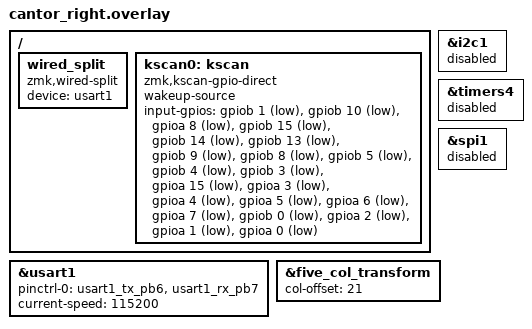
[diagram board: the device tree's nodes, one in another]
/*
 * Cantor right half – peripheral side (connects to left half via TRRS).
 *
 * Same GPIO pin order as the left half (same PCB, just flipped).
 * The col-offset=<21> shifts columns to 21-41, and the matrix transform
 * reverses the column order to handle the physical mirroring.
 *
 * Split communication: USART1 full-duplex on PB6 (TX) / PB7 (RX).
 */

#include "cantor.dtsi"

/*
 * Disable peripherals whose default pins conflict with Cantor GPIOs:
 *   - I2C1 uses PB8/PB9 → conflicts with kscan row-1 keys
 *   - TIM4/PWM4 uses PB6/PB7 → conflicts with USART1 wired split
 *   - SPI1 uses PA5/PA6/PA7 → conflicts with kscan row-2 keys
 */
&i2c1 { status = "disabled"; };
&timers4 { status = "disabled"; };
&spi1 { status = "disabled"; };

/* Remap USART1 to PB6/PB7 (Cantor wiring) and enable for wired split */
&usart1 {
    pinctrl-0 = <&usart1_tx_pb6 &usart1_rx_pb7>;
    pinctrl-names = "default";
    status = "okay";
    current-speed = <115200>;
};

/* Shift right-half column indices by 21 so they don't overlap with left */
&five_col_transform {
    col-offset = <21>;
};

/ {
    wired_split {
        compatible = "zmk,wired-split";
        device = <&usart1>;
    };

    kscan0: kscan {
        compatible = "zmk,kscan-gpio-direct";
        wakeup-source;
        input-gpios =
            <&gpiob 1  (GPIO_ACTIVE_LOW | GPIO_PULL_UP)>   /* row 0 col 0 (outer) */
            , <&gpiob 10 (GPIO_ACTIVE_LOW | GPIO_PULL_UP)> /* row 0 col 1 */
            , <&gpioa 8  (GPIO_ACTIVE_LOW | GPIO_PULL_UP)> /* row 0 col 2 */
            , <&gpiob 15 (GPIO_ACTIVE_LOW | GPIO_PULL_UP)> /* row 0 col 3 */
            , <&gpiob 14 (GPIO_ACTIVE_LOW | GPIO_PULL_UP)> /* row 0 col 4 */
            , <&gpiob 13 (GPIO_ACTIVE_LOW | GPIO_PULL_UP)> /* row 0 col 5 (inner) */
            , <&gpiob 9  (GPIO_ACTIVE_LOW | GPIO_PULL_UP)> /* row 1 col 0 */
            , <&gpiob 8  (GPIO_ACTIVE_LOW | GPIO_PULL_UP)> /* row 1 col 1 */
            , <&gpiob 5  (GPIO_ACTIVE_LOW | GPIO_PULL_UP)> /* row 1 col 2 */
            , <&gpiob 4  (GPIO_ACTIVE_LOW | GPIO_PULL_UP)> /* row 1 col 3 */
            , <&gpiob 3  (GPIO_ACTIVE_LOW | GPIO_PULL_UP)> /* row 1 col 4 */
            , <&gpioa 15 (GPIO_ACTIVE_LOW | GPIO_PULL_UP)> /* row 1 col 5 */
            , <&gpioa 3  (GPIO_ACTIVE_LOW | GPIO_PULL_UP)> /* row 2 col 0 */
            , <&gpioa 4  (GPIO_ACTIVE_LOW | GPIO_PULL_UP)> /* row 2 col 1 */
            , <&gpioa 5  (GPIO_ACTIVE_LOW | GPIO_PULL_UP)> /* row 2 col 2 */
            , <&gpioa 6  (GPIO_ACTIVE_LOW | GPIO_PULL_UP)> /* row 2 col 3 */
            , <&gpioa 7  (GPIO_ACTIVE_LOW | GPIO_PULL_UP)> /* row 2 col 4 */
            , <&gpiob 0  (GPIO_ACTIVE_LOW | GPIO_PULL_UP)> /* row 2 col 5 */
            , <&gpioa 2  (GPIO_ACTIVE_LOW | GPIO_PULL_UP)> /* thumb 0 */
            , <&gpioa 1  (GPIO_ACTIVE_LOW | GPIO_PULL_UP)> /* thumb 1 */
            , <&gpioa 0  (GPIO_ACTIVE_LOW | GPIO_PULL_UP)> /* thumb 2 */
        ;
    };
};
